# ATSAM3SD8B device description
Architecture: CORTEX-M3; Family: SAM3; Series: SAM3SD8
Registers are 32-bit, read-write, no defined reset value unless marked. A register's access mark holds for its fields unless they carry their own. Offsets are from the block's base; [hi:lo] are bit positions; {n}, {i} and the like mark numbered series.

## PDC — Peripheral DMA Controller
0x00 PERIPH_RPR — Receive Pointer Register
  [31:0] RXPTR
0x04 PERIPH_RCR — Receive Counter Register
  [15:0] RXCTR
0x08 PERIPH_TPR — Transmit Pointer Register
  [31:0] TXPTR — Transmit Counter Register
0x0C PERIPH_TCR — Transmit Counter Register
  [15:0] TXCTR
0x10 PERIPH_RNPR — Receive Next Pointer Register
  [31:0] RXNPTR — Receive Next Pointer
0x14 PERIPH_RNCR — Receive Next Counter Register
  [15:0] RXNCTR — Receive Next Counter
0x18 PERIPH_TNPR — Transmit Next Pointer Register
  [31:0] TXNPTR — Transmit Next Pointer
0x1C PERIPH_TNCR — Transmit Next Counter Register
  [15:0] TXNCTR — Transmit Counter Next
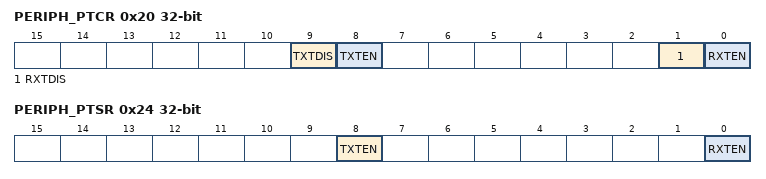
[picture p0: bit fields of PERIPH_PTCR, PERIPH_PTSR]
0x20 PERIPH_PTCR wo — Transfer Control Register
  [9] TXTDIS — Transmitter Transfer Disable
  [8] TXTEN — Transmitter Transfer Enable
  [1] RXTDIS — Receiver Transfer Disable
  [0] RXTEN — Receiver Transfer Enable
0x24 PERIPH_PTSR ro — Transfer Status Register
  [8] TXTEN — Transmitter Transfer Enable
  [0] RXTEN — Receiver Transfer Enable

## RSTC — Reset Controller
Instances: RSTC 0x400E1400
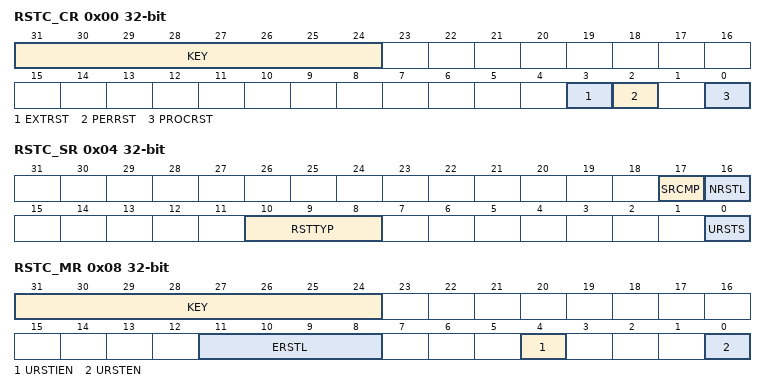
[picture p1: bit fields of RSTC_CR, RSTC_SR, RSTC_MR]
0x00 RSTC_CR wo — Control Register
  [31:24] KEY — System Reset Key
  [3] EXTRST — External Reset
  [2] PERRST — Peripheral Reset
  [0] PROCRST — Processor Reset
0x04 RSTC_SR ro — Status Register
  [17] SRCMP — Software Reset Command in Progress
  [16] NRSTL — NRST Pin Level
  [10:8] RSTTYP — Reset Type
  [0] URSTS — User Reset Status
0x08 RSTC_MR — Mode Register
  [31:24] KEY — Password
  [11:8] ERSTL — External Reset Length
  [4] URSTIEN — User Reset Interrupt Enable
  [0] URSTEN — User Reset Enable

## RTT — Real-time Timer
Instances: RTT 0x400E1430
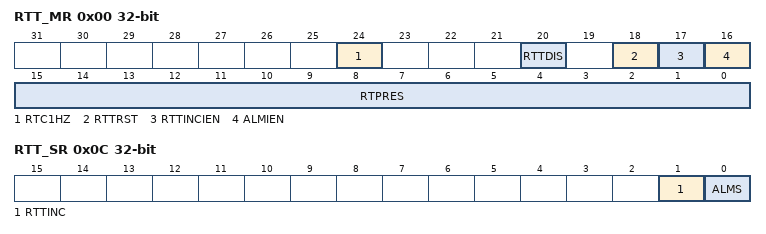
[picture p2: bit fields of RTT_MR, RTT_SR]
0x00 RTT_MR — Mode Register
  [24] RTC1HZ — Real-Time Clock 1Hz Clock Selection
  [20] RTTDIS — Real-time Timer Disable
  [18] RTTRST — Real-time Timer Restart
  [17] RTTINCIEN — Real-time Timer Increment Interrupt Enable
  [16] ALMIEN — Alarm Interrupt Enable
  [15:0] RTPRES — Real-time Timer Prescaler Value
0x04 RTT_AR — Alarm Register
  [31:0] ALMV — Alarm Value
0x08 RTT_VR ro — Value Register
  [31:0] CRTV — Current Real-time Value
0x0C RTT_SR ro — Status Register
  [1] RTTINC — Real-time Timer Increment
  [0] ALMS — Real-time Alarm Status

## UDP — USB Device Port
Instances: UDP 0x40034000
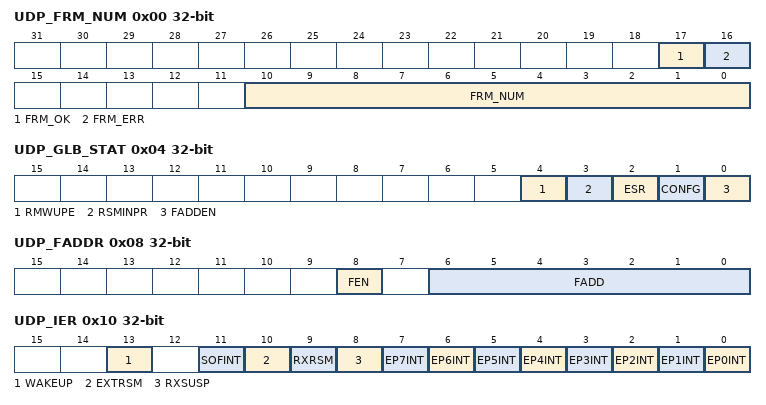
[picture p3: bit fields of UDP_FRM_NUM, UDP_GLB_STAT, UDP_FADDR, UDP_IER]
0x00 UDP_FRM_NUM ro — Frame Number Register
  [17] FRM_OK — Frame OK
  [16] FRM_ERR — Frame Error
  [10:0] FRM_NUM — Frame Number as Defined in the Packet Field Formats
0x04 UDP_GLB_STAT — Global State Register
  [4] RMWUPE — Remote Wake Up Enable
  [3] RSMINPR
  [2] ESR — Enable Send Resume
  [1] CONFG — Configured
  [0] FADDEN — Function Address Enable
0x08 UDP_FADDR — Function Address Register
  [8] FEN — Function Enable
  [6:0] FADD — Function Address Value
0x10 UDP_IER wo — Interrupt Enable Register
  [13] WAKEUP — Enable UDP bus Wakeup Interrupt
  [11] SOFINT — Enable Start Of Frame Interrupt
  [10] EXTRSM
  [9] RXRSM — Enable UDP Resume Interrupt
  [8] RXSUSP — Enable UDP Suspend Interrupt
  [n] EP{n}INT (n=3..7) — Enable Endpoint {n} Interrupt
  [2] EP2INT — Enable Endpoint 2Interrupt
  [1] EP1INT — Enable Endpoint 1 Interrupt
  [0] EP0INT — Enable Endpoint 0 Interrupt
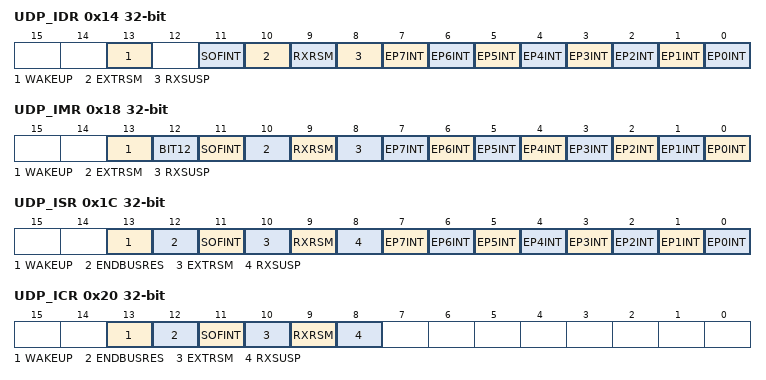
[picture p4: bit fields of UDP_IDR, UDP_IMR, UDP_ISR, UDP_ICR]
0x14 UDP_IDR wo — Interrupt Disable Register
  [13] WAKEUP — Disable USB Bus Interrupt
  [11] SOFINT — Disable Start Of Frame Interrupt
  [10] EXTRSM
  [9] RXRSM — Disable UDP Resume Interrupt
  [8] RXSUSP — Disable UDP Suspend Interrupt
  [n] EP{n}INT (n=0..7) — Disable Endpoint {n} Interrupt
0x18 UDP_IMR ro — Interrupt Mask Register
  [13] WAKEUP — USB Bus WAKEUP Interrupt
  [12] BIT12 — UDP_IMR Bit 12
  [11] SOFINT — Mask Start Of Frame Interrupt
  [10] EXTRSM
  [9] RXRSM — Mask UDP Resume Interrupt.
  [8] RXSUSP — Mask UDP Suspend Interrupt
  [n] EP{n}INT (n=0..7) — Mask Endpoint {n} Interrupt
0x1C UDP_ISR ro — Interrupt Status Register
  [13] WAKEUP — UDP Resume Interrupt Status
  [12] ENDBUSRES — End of BUS Reset Interrupt Status
  [11] SOFINT — Start of Frame Interrupt Status
  [10] EXTRSM
  [9] RXRSM — UDP Resume Interrupt Status
  [8] RXSUSP — UDP Suspend Interrupt Status
  [7] EP7INT — Endpoint 7Interrupt Status
  [n] EP{n}INT (n=0..6) — Endpoint {n} Interrupt Status
0x20 UDP_ICR wo — Interrupt Clear Register
  [13] WAKEUP — Clear Wakeup Interrupt
  [12] ENDBUSRES — Clear End of Bus Reset Interrupt
  [11] SOFINT — Clear Start Of Frame Interrupt
  [10] EXTRSM
  [9] RXRSM — Clear UDP Resume Interrupt
  [8] RXSUSP — Clear UDP Suspend Interrupt
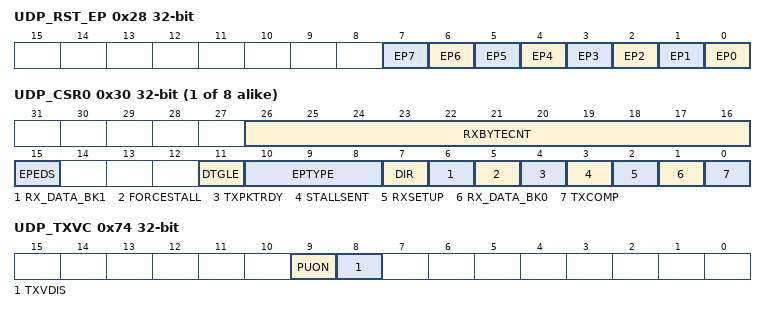
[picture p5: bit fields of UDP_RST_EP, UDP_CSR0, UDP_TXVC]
0x28 UDP_RST_EP — Reset Endpoint Register
  [n] EP{n} (n=0..7) — Reset Endpoint {n}
{0x30+4i} UDP_CSR{i} (i=0..7) — Endpoint Control and Status Register {i}
  [26:16] RXBYTECNT — Number of Bytes Available in the FIFO
  [15] EPEDS — Endpoint Enable Disable
  [11] DTGLE — Data Toggle
  [10:8] EPTYPE — Endpoint Type
    0=CTRL (Control); 1=ISO_OUT (Isochronous OUT); 2=BULK_OUT; 3=INT_OUT (Interrupt OUT); 5=ISO_IN (Isochronous IN); 6=BULK_IN; 7=INT_IN (Interrupt IN)
  [7] DIR — Transfer Direction (only available for control endpoints)
  [6] RX_DATA_BK1 — Receive Data Bank 1 (only used by endpoints with ping-pong attributes)
  [5] FORCESTALL — Force Stall (used by Control, Bulk and Isochronous Endpoints)
  [4] TXPKTRDY — Transmit Packet Ready
  [3] STALLSENT
  [2] RXSETUP — Received Setup
  [1] RX_DATA_BK0 — Receive Data Bank 0
  [0] TXCOMP — Generates an IN Packet with Data Previously Written in the DPR
{0x50+4i} UDP_FDR{i} (i=0..7) — Endpoint FIFO Data Register {i}
  [7:0] FIFO_DATA — FIFO Data Value
0x74 UDP_TXVC — Transceiver Control Register
  [9] PUON — Pull-up On
  [8] TXVDIS — Transceiver Disable

## WDT — Watchdog Timer
Instances: WDT 0x400E1450
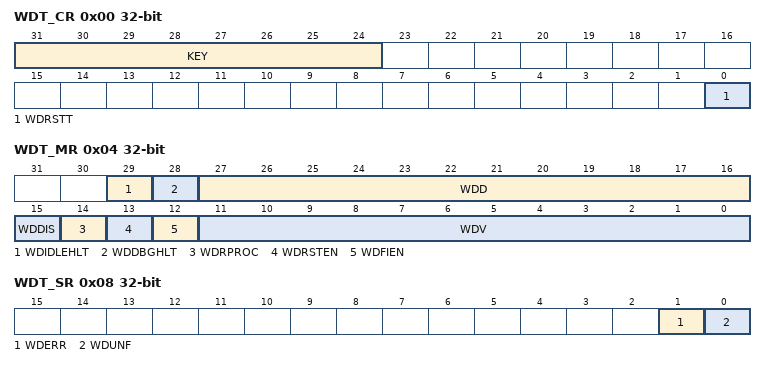
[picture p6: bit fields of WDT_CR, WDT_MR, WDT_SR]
0x00 WDT_CR wo — Control Register
  [31:24] KEY — Password
  [0] WDRSTT — Watchdog Restart
0x04 WDT_MR — Mode Register
  [29] WDIDLEHLT — Watchdog Idle Halt
  [28] WDDBGHLT — Watchdog Debug Halt
  [27:16] WDD — Watchdog Delta Value
  [15] WDDIS — Watchdog Disable
  [14] WDRPROC — Watchdog Reset Processor
  [13] WDRSTEN — Watchdog Reset Enable
  [12] WDFIEN — Watchdog Fault Interrupt Enable
  [11:0] WDV — Watchdog Counter Value
0x08 WDT_SR ro — Status Register
  [1] WDERR — Watchdog Error
  [0] WDUNF — Watchdog Underflow

## GPNVMBITS (FUSES module)
Instances: GPNVMBITS 0 in fuses
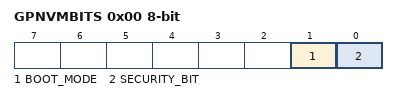
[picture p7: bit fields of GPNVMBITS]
0x00 GPNVMBITS 8-bit
  [1] BOOT_MODE — Boot Mode Selection
  [0] SECURITY_BIT ro

## LOCKBIT
Instances: LOCKBIT 0 in lockbits
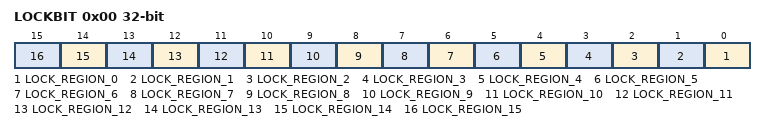
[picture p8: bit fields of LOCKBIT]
0x00 LOCKBIT — Lock Bits
  [n] LOCK_REGION_{n} (n=0..15)

## SysTick — System timer
Instances: SysTick 0xE000E010
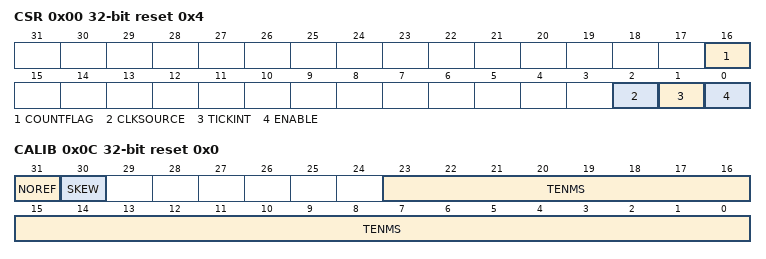
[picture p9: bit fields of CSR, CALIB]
0x00 CSR access not given reset 0x4 — SysTick Control and Status Register
  [16] COUNTFLAG
  [2] CLKSOURCE
    0=external clock; 1=processor clock
  [1] TICKINT
    0=counting down to 0 does not assert the SysTick exception request; 1=counting down to 0 asserts the SysTick exception request
  [0] ENABLE
    0=counter disabled; 1=counter enabled
0x04 RVR access not given reset 0x0 — SysTick Reload Value Register
  [23:0] RELOAD — Value to load into the SysTick Current Value Register when the counter reaches 0
0x08 CVR access not given reset 0x0 — SysTick Current Value Register
  [23:0] CURRENT — Current value at the time the register is accessed
0x0C CALIB access not given reset 0x0 — SysTick Calibration Value Register
  [31] NOREF
    0=The reference clock is provided; 1=The reference clock is not provided
  [30] SKEW
    0=10ms calibration value is exact; 1=10ms calibration value is inexact, because of the clock frequency
  [23:0] TENMS — Reload value to use for 10ms timing

## NVIC — Nested Vectored Interrupt Controller
Instances: NVIC 0xE000E100
{0x0+4i} NVICISER{i} access not given reset 0x0 (i=0..3) — Interrupt Set Enable Register n
  [31:0] SETENA — Interrupt set enable bits
{0x80+4i} NVICICER{i} access not given reset 0x0 (i=0..3) — Interrupt Clear Enable Register n
  [31:0] CLRENA — Interrupt clear-enable bits
{0x100+4i} NVICISPR{i} access not given reset 0x0 (i=0..3) — Interrupt Set Pending Register n
  [31:0] SETPEND — Interrupt set-pending bits
{0x180+4i} NVICICPR{i} access not given reset 0x0 (i=0..3) — Interrupt Clear Pending Register n
  [31:0] CLRPEND — Interrupt clear-pending bits
{0x200+4i} NVICIABR{i} access not given reset 0x0 (i=0..3) — Interrupt Active bit Register n
  [31:0] ACTIVE — Interrupt active flags
{0x300+i} NVICIP{i} 8-bit access not given reset 0x0 (i=0..105) — Interrupt Priority Register n
  [7:0] PRI{i} — Priority of interrupt {i}
0xE00 NVICSTIR access not given reset 0x0 — Software Trigger Interrupt Register
  [8:0] INTID — Interrupt ID of the interrupt to trigger, in the range 0-239. For example, a value of 0x03 specifies interrupt IRQ3.

## Notices in the file
SAM Software Package License
Copyright (c) %copyright_year%, Atmel Corporation
All rights reserved.
Redistribution and use in source and binary forms, with or without
modification, are permitted provided that the following condition is met:
- Redistributions of source code must retain the above copyright notice,
this list of conditions and the disclaimer below.
Atmel's name may not be used to endorse or promote products derived from
this software without specific prior written permission.
DISCLAIMER:  THIS SOFTWARE IS PROVIDED BY ATMEL "AS IS" AND ANY EXPRESS OR
IMPLIED WARRANTIES, INCLUDING, BUT NOT LIMITED TO, THE IMPLIED WARRANTIES OF
MERCHANTABILITY, FITNESS FOR A PARTICULAR PURPOSE AND NON-INFRINGEMENT ARE
DISCLAIMED. IN NO EVENT SHALL ATMEL BE LIABLE FOR ANY DIRECT, INDIRECT,
INCIDENTAL, SPECIAL, EXEMPLARY, OR CONSEQUENTIAL DAMAGES (INCLUDING, BUT NOT
LIMITED TO, PROCUREMENT OF SUBSTITUTE GOODS OR SERVICES; LOSS OF USE, DATA,
OR PROFITS; OR BUSINESS INTERRUPTION) HOWEVER CAUSED AND ON ANY THEORY OF
LIABILITY, WHETHER IN CONTRACT, STRICT LIABILITY, OR TORT (INCLUDING
NEGLIGENCE OR OTHERWISE) ARISING IN ANY WAY OUT OF THE USE OF THIS SOFTWARE,
EVEN IF ADVISED OF THE POSSIBILITY OF SUCH DAMAGE.
